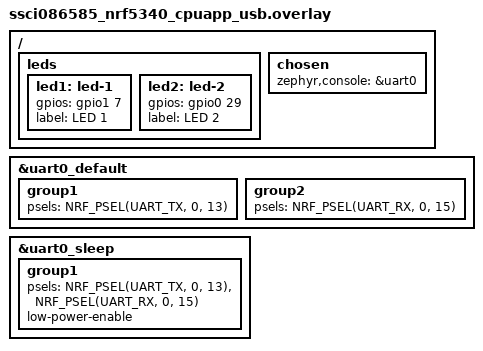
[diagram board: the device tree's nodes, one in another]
// To get started, press Ctrl+Space to bring up the completion menu and view the available nodes.

// You can also use the buttons in the sidebar to perform actions on nodes.
// Actions currently available include:

// * Enabling / disabling the node
// * Adding the bus to a bus
// * Removing the node
// * Connecting ADC channels

// For more help, browse the DeviceTree documentation at https://docs.zephyrproject.org/latest/guides/dts/index.html
// You can also visit the nRF DeviceTree extension documentation at https://docs.nordicsemi.com/bundle/nrf-connect-vscode/page/guides/ncs_configure_app.html#devicetree-support-in-the-extension

/ {
	leds {
		led1: led-1 {
			gpios = <&gpio1 7 0>;
			label = "LED 1";
		};

		led2: led-2 {
			gpios = <&gpio0 29 0>;
			label = "LED 2";
		};
	};

	chosen {
		zephyr,console = &uart0;
	};
};

/delete-node/ &{/pin-controller/qspi_default/group1/};
/delete-node/ &{/pin-controller/qspi_sleep/group1/};

&uart0_default {
	group1 {
		psels = <NRF_PSEL(UART_TX, 0, 13)>;
	};
	group2 {
		psels = <NRF_PSEL(UART_RX, 0, 15)>;
	};
};

&uart0_sleep {
	group1 {
		psels = <NRF_PSEL(UART_TX, 0, 13)>,
				<NRF_PSEL(UART_RX, 0, 15)>;
		low-power-enable;
	};
};
